AUTOSAR XML (schema 00046)
package /Appl_ComShell/ImplementationDataTypes
  19 x impl type, all with category=STRUCTURE:
    CrashStsSafe_1
      element Sts: implementation-data-type=uint8
      element Chks: implementation-data-type=uint8
      element Cntr: implementation-data-type=uint8
    EngSt1WdSts_1
      element EngSt1WdSts: implementation-data-type=uint8
      element Chks: implementation-data-type=uint8
      element Cntr: implementation-data-type=uint8
    EscVariantToDmc_1
      element EscVariantToDmc: implementation-data-type=uint8
      element Chks: implementation-data-type=uint8
      element Cntr: implementation-data-type=uint8
    HvSysRlySts_1
      element HvSysRlySts: implementation-data-type=uint8
      element Cntr: implementation-data-type=uint8
      element Chks: implementation-data-type=uint8
    PtTqAtAxleReq_1
      4 x element, all with category=TYPE_REFERENCE:
        PtTqAtAxleFrntReq: implementation-data-type=sint16
        PtTqAtAxleReReq: implementation-data-type=sint16
        Chks: implementation-data-type=uint8
        Cntr: implementation-data-type=uint8
    StcStsToDmc_1
      6 x element, all with category=TYPE_REFERENCE:
        StcStsToDmcFrnt: implementation-data-type=uint8
        StcStsToDmcRear: implementation-data-type=uint8
        EngRotTarSpdDMCFrnt: implementation-data-type=uint16
        EngRotTarSpdDMCRear: implementation-data-type=uint16
        Chks: implementation-data-type=uint8
        Cntr: implementation-data-type=uint8
    VehModMngtGlbSafe1_2
      10 x element, all with category=TYPE_REFERENCE, implementation-data-type=uint8:
        UsgModSts
        CarModSts1
        CarModSubtypWdCarModSubtyp
        EgyLvlElecMai
        EgyLvlElecSubtyp
        PwrLvlElecMai
        PwrLvlElecSubtyp
        FltEgyCnsWdSts
        Chks
        Cntr
    VehMtnStSafe1_2
      element VehMtnSt: implementation-data-type=uint8
      element VehMtnStChks: implementation-data-type=uint8
      element VehMtnStCntr: implementation-data-type=uint8
    VehSpdLgtSafe1_3
      4 x element, all with category=TYPE_REFERENCE:
        VehSpdLgtA: implementation-data-type=uint16
        VehSpdLgtQf: implementation-data-type=uint8
        VehSpdLgtCntr: implementation-data-type=uint8
        VehSpdLgtChks: implementation-data-type=uint8
    WhlMotSysTqAllwd_3
      element WhlMotSysTqAllwd: implementation-data-type=uint8
      element Chks: implementation-data-type=uint8
      element Cntr: implementation-data-type=uint8
    ImobEngMgrReq_2
      8 x element, all with category=TYPE_REFERENCE, implementation-data-type=uint8:
        ImobEngMgrCmdTar1
        ImobEngDataMgrReq{0..6}
    SysU_4
      element SysU: implementation-data-type=uint8
      element SysUQf: implementation-data-type=uint8
    DmcStsToEsc_1
      5 x element, all with category=TYPE_REFERENCE:
        DmcSts: implementation-data-type=uint8
        DmcActAppTarTq: implementation-data-type=sint16
        Cntr: implementation-data-type=uint8
        Chks: implementation-data-type=uint8
        DmcSWInfo: implementation-data-type=uint16
    SpdSgnSafe_1
      4 x element, all with category=TYPE_REFERENCE:
        IsgSpdWSgnTyp: implementation-data-type=sint16
        Chks: implementation-data-type=uint8
        Cntr: implementation-data-type=uint8
        Qf: implementation-data-type=uint8
    IsgTqActSafe2_4
      4 x element, all with category=TYPE_REFERENCE:
        Cntr: implementation-data-type=uint8
        Chks: implementation-data-type=uint8
        QualityFactor: implementation-data-type=uint8
        IsgTqAct: implementation-data-type=uint16
    DevDataTyp64_2
      8 x element, all with category=TYPE_REFERENCE, implementation-data-type=uint8:
        Byte{0..7}
    ElecDrvGen_4
      16 x element, all with category=TYPE_REFERENCE, implementation-data-type=uint8:
        EMQnty
        EMSeqNr
        DTCSts
        DTCLow
        DTCMid
        DTCHig
        TypeInfo
        MotTAlrmSt
        InvrtTAlrmSt
        FltAlrmSt
        SpdAlrmSt
        IacAlrmSt
        UDcAlrmSt
        RslAlrmSt
        ADAlrmSt
        ModStatusRms
    ImobEngChk_2
      8 x element, all with category=TYPE_REFERENCE, implementation-data-type=uint8:
        ImobEngChkSts
        ImobEngDataChk{0..6}
    WhlMotSysTqAvl_2
      element TqAvlMax: implementation-data-type=uint16
      element TqAvlMin: implementation-data-type=uint16
package /Appl_ComShell/DataTypeMappingSets
  data type mapping set Appl_ComShell_DTMap
    data-type-maps:
      application-data-type=AlrmSt_2, implementation-data-type=uint8
      application-data-type=Ampr1_1, implementation-data-type=uint16
      application-data-type=AvlSts2_2, implementation-data-type=uint8
      application-data-type=CarModSts1_2, implementation-data-type=uint8
      application-data-type=CarTiGlb_2, implementation-data-type=uint32
      application-data-type=CooltFlow2_2, implementation-data-type=uint16
      application-data-type=CooltFlowForDtElec1_2, implementation-data-type=uint16
      application-data-type=CooltTHiResl_2, implementation-data-type=uint16
      application-data-type=CrashSts2_2, implementation-data-type=uint8
      application-data-type=DMC_1, implementation-data-type=uint8
      application-data-type=EngSt1_2, implementation-data-type=uint8
      application-data-type=FltEgyCns1_2, implementation-data-type=uint8
      application-data-type=FltIndcn_1, implementation-data-type=uint8
      application-data-type=FltLvl_1, implementation-data-type=uint8
      application-data-type=FrntHeatModEnad_1, implementation-data-type=uint8
      application-data-type=GearLvrIndcn2_2, implementation-data-type=uint8
      application-data-type=GenQf1_2, implementation-data-type=uint8
      application-data-type=HvActvnSts_2, implementation-data-type=uint8
      application-data-type=HvCoolg1_2, implementation-data-type=uint8
      application-data-type=HvT1_3, implementation-data-type=uint8
      application-data-type=HvTq1_2, implementation-data-type=uint16
      application-data-type=HvU1_2, implementation-data-type=uint16
      application-data-type=ImobEngMgrReqCmd_2, implementation-data-type=uint8
      application-data-type=ImobSts_2, implementation-data-type=uint8
      application-data-type=IsgHeatPwr_1, implementation-data-type=uint8
      application-data-type=IsgSpdWSgnTyp_2, implementation-data-type=sint16
      application-data-type=Len31_2, implementation-data-type=uint32
      application-data-type=ModStatusRms_2, implementation-data-type=uint8
      application-data-type=ModeDMC_1, implementation-data-type=uint8
      application-data-type=N1_2, implementation-data-type=uint16
      application-data-type=Nr5_2, implementation-data-type=uint8
      application-data-type=OnBdChrgrHndlSts1_2, implementation-data-type=uint8
      application-data-type=OnBdChrgrHndlSts_2, implementation-data-type=uint8
      application-data-type=OnOff1_2, implementation-data-type=uint8
      application-data-type=PLockParkRequest_1, implementation-data-type=uint8
      application-data-type=ParkSts_1, implementation-data-type=uint8
      application-data-type=Perc7_2, implementation-data-type=uint16
      application-data-type=PrpsnPwrLimMax_2, implementation-data-type=uint16
      application-data-type=PrpsnPwrLimMin_2, implementation-data-type=uint16
      application-data-type=QualityFactor_2, implementation-data-type=uint8
      application-data-type=Spd1_2, implementation-data-type=uint16
      application-data-type=T3_2, implementation-data-type=uint8
      application-data-type=Tq2_2, implementation-data-type=sint16
      application-data-type=Tq34_1, implementation-data-type=uint16
      application-data-type=Tq35_1, implementation-data-type=sint16
      application-data-type=U1_2, implementation-data-type=uint8
      application-data-type=UInt16_2, implementation-data-type=uint16
      application-data-type=UInt2_2, implementation-data-type=uint8
      application-data-type=UInt4_2, implementation-data-type=uint8
      application-data-type=UInt8_2, implementation-data-type=uint8
      application-data-type=UsgModSts1_2, implementation-data-type=uint8
      application-data-type=VehMtnSt2_2, implementation-data-type=uint8
      application-data-type=WhlMotSysActvDampgModCodSts_2, implementation-data-type=uint8
      application-data-type=WhlMotSysHeatFdBck_1, implementation-data-type=uint8
      application-data-type=WhlMotSysModStsTyp1_2, implementation-data-type=uint8
      application-data-type=WhlMotSysModStsTyp2_2, implementation-data-type=uint8
      application-data-type=CrashStsSafe_1, implementation-data-type=CrashStsSafe_1
      application-data-type=EngSt1WdSts_1, implementation-data-type=EngSt1WdSts_1
      application-data-type=EscVariantToDmc_1, implementation-data-type=EscVariantToDmc_1
      application-data-type=HvSysRlySts_1, implementation-data-type=HvSysRlySts_1
      application-data-type=PtTqAtAxleReq_1, implementation-data-type=PtTqAtAxleReq_1
      application-data-type=StcStsToDmc_1, implementation-data-type=StcStsToDmc_1
      application-data-type=VehModMngtGlbSafe1_2, implementation-data-type=VehModMngtGlbSafe1_2
      application-data-type=VehMtnStSafe1_2, implementation-data-type=VehMtnStSafe1_2
      application-data-type=VehSpdLgtSafe1_3, implementation-data-type=VehSpdLgtSafe1_3
      application-data-type=WhlMotSysTqAllwd_3, implementation-data-type=WhlMotSysTqAllwd_3
      application-data-type=ImobEngMgrReq_2, implementation-data-type=ImobEngMgrReq_2
      application-data-type=SysU_4, implementation-data-type=SysU_4
      application-data-type=DmcStsToEsc_1, implementation-data-type=DmcStsToEsc_1
      application-data-type=SpdSgnSafe_1, implementation-data-type=SpdSgnSafe_1
      application-data-type=IsgTqActSafe2_4, implementation-data-type=IsgTqActSafe2_4
      application-data-type=DevDataTyp64_2, implementation-data-type=DevDataTyp64_2
      application-data-type=ElecDrvGen_4, implementation-data-type=ElecDrvGen_4
      application-data-type=ImobEngChk_2, implementation-data-type=ImobEngChk_2
      application-data-type=WhlMotSysTqAvl_2, implementation-data-type=WhlMotSysTqAvl_2
package /Appl_ComShell/ComponentTypes
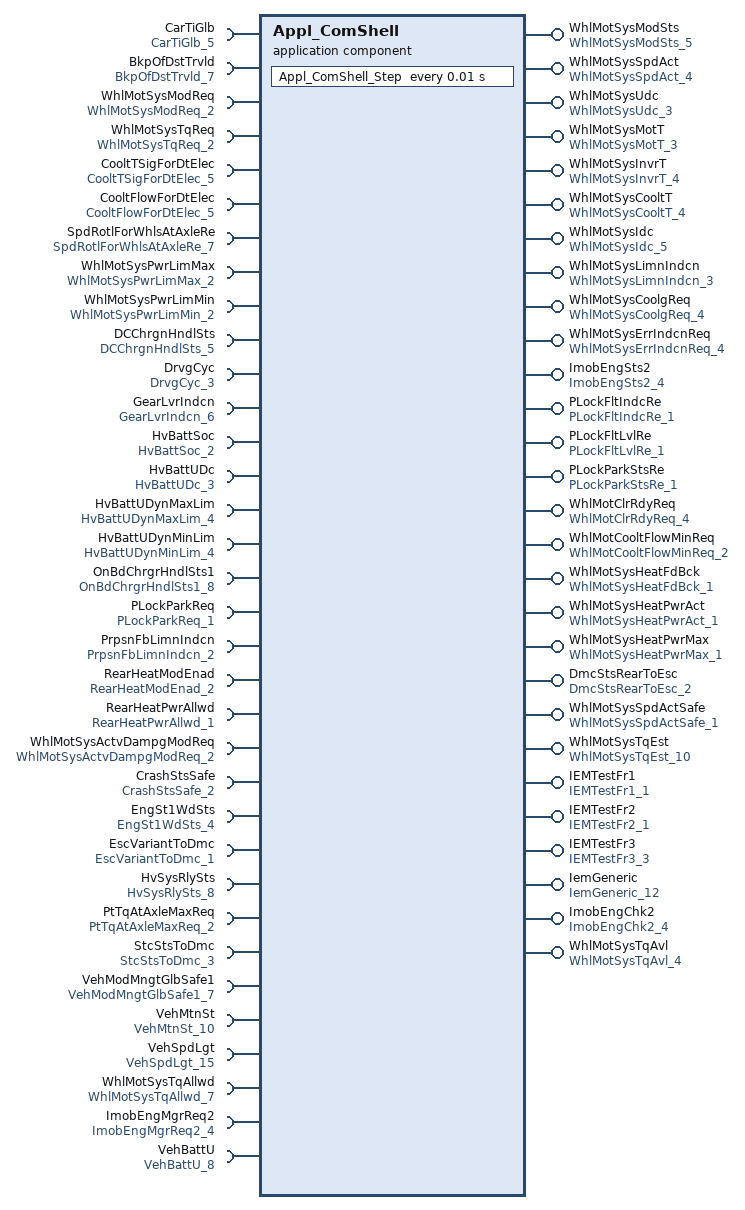
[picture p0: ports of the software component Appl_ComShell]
  application sw component type Appl_ComShell
    9 x require port:
      CarTiGlb: nonqueued-receiver-com-spec{data-element=CarTiGlb, init-value=0}, required-interface=CarTiGlb_5
      BkpOfDstTrvld: nonqueued-receiver-com-spec{data-element=BkpOfDstTrvld, init-value=0}, required-interface=BkpOfDstTrvld_7
      WhlMotSysModReq: nonqueued-receiver-com-spec{data-element=WhlMotSysModReq, init-value=0}, required-interface=WhlMotSysModReq_2
      WhlMotSysTqReq: nonqueued-receiver-com-spec{data-element=WhlMotSysTqReq, init-value=0}, required-interface=WhlMotSysTqReq_2
      CooltTSigForDtElec: nonqueued-receiver-com-spec{data-element=CooltTSigForDtElec, init-value=0}, required-interface=CooltTSigForDtElec_5
      CooltFlowForDtElec: nonqueued-receiver-com-spec{data-element=CooltFlowForDtElec, init-value=0}, required-interface=CooltFlowForDtElec_5
      SpdRotlForWhlsAtAxleRe: nonqueued-receiver-com-spec{data-element=SpdRotlForWhlsAtAxleRe, init-value=0}, required-interface=SpdRotlForWhlsAtAxleRe_7
      WhlMotSysPwrLimMax: nonqueued-receiver-com-spec{data-element=WhlMotSysPwrLimMax, init-value=0}, required-interface=WhlMotSysPwrLimMax_2
      WhlMotSysPwrLimMin: nonqueued-receiver-com-spec{data-element=WhlMotSysPwrLimMin, init-value=0}, required-interface=WhlMotSysPwrLimMin_2
    10 x provide port:
      WhlMotSysModSts: nonqueued-sender-com-spec{data-element=WhlMotSysModSts, init-value=0}, provided-interface=WhlMotSysModSts_5
      WhlMotSysSpdAct: nonqueued-sender-com-spec{data-element=WhlMotSysSpdAct, init-value=0}, provided-interface=WhlMotSysSpdAct_4
      WhlMotSysUdc: nonqueued-sender-com-spec{data-element=WhlMotSysUdc, init-value=0}, provided-interface=WhlMotSysUdc_3
      WhlMotSysMotT: nonqueued-sender-com-spec{data-element=WhlMotSysMotT, init-value=0}, provided-interface=WhlMotSysMotT_3
      WhlMotSysInvrT: nonqueued-sender-com-spec{data-element=WhlMotSysInvrT, init-value=0}, provided-interface=WhlMotSysInvrT_4
      WhlMotSysCooltT: nonqueued-sender-com-spec{data-element=WhlMotSysCooltT, init-value=0}, provided-interface=WhlMotSysCooltT_4
      WhlMotSysIdc: nonqueued-sender-com-spec{data-element=WhlMotSysIdc, init-value=0}, provided-interface=WhlMotSysIdc_5
      WhlMotSysLimnIndcn: nonqueued-sender-com-spec{data-element=WhlMotSysLimnIndcn, init-value=0}, provided-interface=WhlMotSysLimnIndcn_3
      WhlMotSysCoolgReq: nonqueued-sender-com-spec{data-element=WhlMotSysCoolgReq, init-value=0}, provided-interface=WhlMotSysCoolgReq_4
      WhlMotSysErrIndcnReq: nonqueued-sender-com-spec{data-element=WhlMotSysErrIndcnReq, init-value=0}, provided-interface=WhlMotSysErrIndcnReq_4
    7 x require port:
      DCChrgnHndlSts: nonqueued-receiver-com-spec{data-element=DCChrgnHndlSts, init-value=0}, required-interface=DCChrgnHndlSts_5
      DrvgCyc: nonqueued-receiver-com-spec{data-element=DrvgCyc, init-value=0}, required-interface=DrvgCyc_3
      GearLvrIndcn: nonqueued-receiver-com-spec{data-element=GearLvrIndcn, init-value=0}, required-interface=GearLvrIndcn_6
      HvBattSoc: nonqueued-receiver-com-spec{data-element=HvBattSoc, init-value=0}, required-interface=HvBattSoc_2
      HvBattUDc: nonqueued-receiver-com-spec{data-element=HvBattUDc, init-value=0}, required-interface=HvBattUDc_3
      HvBattUDynMaxLim: nonqueued-receiver-com-spec{data-element=HvBattUDynMaxLim, init-value=0}, required-interface=HvBattUDynMaxLim_4
      HvBattUDynMinLim: nonqueued-receiver-com-spec{data-element=HvBattUDynMinLim, init-value=0}, required-interface=HvBattUDynMinLim_4
    provide port ImobEngSts2: nonqueued-sender-com-spec{data-element=ImobEngSts2, init-value=0}, provided-interface=ImobEngSts2_4
    require port OnBdChrgrHndlSts1: nonqueued-receiver-com-spec{data-element=OnBdChrgrHndlSts1, init-value=0}, required-interface=OnBdChrgrHndlSts1_8
    provide port PLockFltIndcRe: nonqueued-sender-com-spec{data-element=PLockFltIndcRe, init-value=0}, provided-interface=PLockFltIndcRe_1
    provide port PLockFltLvlRe: nonqueued-sender-com-spec{data-element=PLockFltLvlRe, init-value=0}, provided-interface=PLockFltLvlRe_1
    require port PLockParkReq: nonqueued-receiver-com-spec{data-element=PLockParkReq, init-value=0}, required-interface=PLockParkReq_1
    provide port PLockParkStsRe: nonqueued-sender-com-spec{data-element=PLockParkStsRe, init-value=0}, provided-interface=PLockParkStsRe_1
    require port PrpsnFbLimnIndcn: nonqueued-receiver-com-spec{data-element=PrpsnFbLimnIndcn, init-value=0}, required-interface=PrpsnFbLimnIndcn_2
    require port RearHeatModEnad: nonqueued-receiver-com-spec{data-element=RearHeatModEnad, init-value=0}, required-interface=RearHeatModEnad_2
    require port RearHeatPwrAllwd: nonqueued-receiver-com-spec{data-element=RearHeatPwrAllwd, init-value=0}, required-interface=RearHeatPwrAllwd_1
    provide port WhlMotClrRdyReq: nonqueued-sender-com-spec{data-element=WhlMotClrRdyReq, init-value=0}, provided-interface=WhlMotClrRdyReq_4
    provide port WhlMotCooltFlowMinReq: nonqueued-sender-com-spec{data-element=WhlMotCooltFlowMinReq, init-value=0}, provided-interface=WhlMotCooltFlowMinReq_2
    require port WhlMotSysActvDampgModReq: nonqueued-receiver-com-spec{data-element=WhlMotSysActvDampgModReq, init-value=0}, required-interface=WhlMotSysActvDampgModReq_2
    provide port WhlMotSysHeatFdBck: nonqueued-sender-com-spec{data-element=WhlMotSysHeatFdBck, init-value=0}, provided-interface=WhlMotSysHeatFdBck_1
    provide port WhlMotSysHeatPwrAct: nonqueued-sender-com-spec{data-element=WhlMotSysHeatPwrAct, init-value=0}, provided-interface=WhlMotSysHeatPwrAct_1
    provide port WhlMotSysHeatPwrMax: nonqueued-sender-com-spec{data-element=WhlMotSysHeatPwrMax, init-value=0}, provided-interface=WhlMotSysHeatPwrMax_1
    12 x require port:
      CrashStsSafe: nonqueued-receiver-com-spec{data-element=CrashStsSafe, init-value=fields=[Sts:0, Chks:0, Cntr:0]}, required-interface=CrashStsSafe_2
      EngSt1WdSts: nonqueued-receiver-com-spec{data-element=EngSt1WdSts, init-value=fields=[EngSt1WdSts:0, Chks:0, Cntr:0]}, required-interface=EngSt1WdSts_4
      EscVariantToDmc: nonqueued-receiver-com-spec{data-element=EscVariantToDmc, init-value=fields=[EscVariantToDmc:0, Chks:0, Cntr:0]}, required-interface=EscVariantToDmc_1
      HvSysRlySts: nonqueued-receiver-com-spec{data-element=HvSysRlySts, init-value=fields=[HvSysRlySts:0, Cntr:0, Chks:0]}, required-interface=HvSysRlySts_8
      PtTqAtAxleMaxReq: nonqueued-receiver-com-spec{data-element=PtTqAtAxleMaxReq, init-value=fields=[PtTqAtAxleFrntReq:0, PtTqAtAxleReReq:0, Chks:0, Cntr:0]}, required-interface=PtTqAtAxleMaxReq_2
      StcStsToDmc: nonqueued-receiver-com-spec{data-element=StcStsToDmc, init-value=fields=[StcStsToDmcFrnt:0, StcStsToDmcRear:0, EngRotTarSpdDMCFrnt:0, EngRotTarSpdDMCRear:0, Chks:0, Cntr:0]}, required-interface=StcStsToDmc_3
      VehModMngtGlbSafe1: nonqueued-receiver-com-spec{data-element=VehModMngtGlbSafe1, init-value=fields=[UsgModSts:0, CarModSts1:0, CarModSubtypWdCarModSubtyp:0, EgyLvlElecMai:0, EgyLvlElecSubtyp:0, PwrLvlElecMai:0, PwrLvlElecSubtyp:0, FltEgyCnsWdSts:0, Chks:0, Cntr:0]}, required-interface=VehModMngtGlbSafe1_7
      VehMtnSt: nonqueued-receiver-com-spec{data-element=VehMtnSt, init-value=fields=[VehMtnSt:0, VehMtnStChks:0, VehMtnStCntr:0]}, required-interface=VehMtnSt_10
      VehSpdLgt: nonqueued-receiver-com-spec{data-element=VehSpdLgt, init-value=fields=[VehSpdLgtA:0, VehSpdLgtQf:0, VehSpdLgtCntr:0, VehSpdLgtChks:0]}, required-interface=VehSpdLgt_15
      WhlMotSysTqAllwd: nonqueued-receiver-com-spec{data-element=WhlMotSysTqAllwd, init-value=fields=[WhlMotSysTqAllwd:0, Chks:0, Cntr:0]}, required-interface=WhlMotSysTqAllwd_7
      ImobEngMgrReq2: nonqueued-receiver-com-spec{data-element=ImobEngMgrReq2, init-value=fields=[ImobEngMgrCmdTar1:0, ImobEngDataMgrReq0:0, ImobEngDataMgrReq1:0, ImobEngDataMgrReq2:0, ImobEngDataMgrReq3:0, ImobEngDataMgrReq4:0, ImobEngDataMgrReq5:0, ImobEngDataMgrReq6:0]}, required-interface=ImobEngMgrReq2_4
      VehBattU: nonqueued-receiver-com-spec{data-element=VehBattU, init-value=fields=[SysU:0, SysUQf:0]}, required-interface=VehBattU_8
    9 x provide port:
      DmcStsRearToEsc: nonqueued-sender-com-spec{data-element=DmcStsRearToEsc, init-value=fields=[DmcSts:0, DmcActAppTarTq:0, Cntr:0, Chks:0, DmcSWInfo:0]}, provided-interface=DmcStsRearToEsc_2
      WhlMotSysSpdActSafe: nonqueued-sender-com-spec{data-element=WhlMotSysSpdActSafe, init-value=fields=[IsgSpdWSgnTyp:0, Chks:0, Cntr:0, Qf:0]}, provided-interface=WhlMotSysSpdActSafe_1
      WhlMotSysTqEst: nonqueued-sender-com-spec{data-element=WhlMotSysTqEst, init-value=fields=[Cntr:0, Chks:0, QualityFactor:0, IsgTqAct:0]}, provided-interface=WhlMotSysTqEst_10
      IEMTestFr1: nonqueued-sender-com-spec{data-element=IEMTestFr1, init-value=fields=[Byte0:0, Byte1:0, Byte2:0, Byte3:0, Byte4:0, Byte5:0, Byte6:0, Byte7:0]}, provided-interface=IEMTestFr1_1
      IEMTestFr2: nonqueued-sender-com-spec{data-element=IEMTestFr2, init-value=fields=[Byte0:0, Byte1:0, Byte2:0, Byte3:0, Byte4:0, Byte5:0, Byte6:0, Byte7:0]}, provided-interface=IEMTestFr2_1
      IEMTestFr3: nonqueued-sender-com-spec{data-element=IEMTestFr3, init-value=fields=[Byte0:0, Byte1:0, Byte2:0, Byte3:0, Byte4:0, Byte5:0, Byte6:0, Byte7:0]}, provided-interface=IEMTestFr3_3
      IemGeneric: nonqueued-sender-com-spec{data-element=IemGeneric, init-value=fields=[EMQnty:0, EMSeqNr:0, DTCSts:0, DTCLow:0, DTCMid:0, DTCHig:0, TypeInfo:0, MotTAlrmSt:0, InvrtTAlrmSt:0, FltAlrmSt:0, SpdAlrmSt:0, IacAlrmSt:0, UDcAlrmSt:0, RslAlrmSt:0, ADAlrmSt:0, ModStatusRms:0]}, provided-interface=IemGeneric_12
      ImobEngChk2: nonqueued-sender-com-spec{data-element=ImobEngChk2, init-value=fields=[ImobEngChkSts:0, ImobEngDataChk0:0, ImobEngDataChk1:0, ImobEngDataChk2:0, ImobEngDataChk3:0, ImobEngDataChk4:0, ImobEngDataChk5:0, ImobEngDataChk6:0]}, provided-interface=ImobEngChk2_4
      WhlMotSysTqAvl: nonqueued-sender-com-spec{data-element=WhlMotSysTqAvl, init-value=fields=[TqAvlMax:0, TqAvlMin:0]}, provided-interface=WhlMotSysTqAvl_4
    behavior Appl_ComShellInternalBehavior: data-type-mapping=Appl_ComShell_DTMap, handle-termination-and-restart=NO-SUPPORT
      timing event RE_Appl_ComShell_Step: start-on-event=Appl_ComShell_Step, period=0.01
      runnable Appl_ComShell_Step
        data-receive-point-by-arguments:
          34 x access:
            DRA_CarTiGlb: accessed-variable=CarTiGlb.CarTiGlb
            DRA_BkpOfDstTrvld: accessed-variable=BkpOfDstTrvld.BkpOfDstTrvld
            DRA_WhlMotSysModReq: accessed-variable=WhlMotSysModReq.WhlMotSysModReq
            DRA_WhlMotSysTqReq: accessed-variable=WhlMotSysTqReq.WhlMotSysTqReq
            DRA_CooltTSigForDtElec: accessed-variable=CooltTSigForDtElec.CooltTSigForDtElec
            DRA_CooltFlowForDtElec: accessed-variable=CooltFlowForDtElec.CooltFlowForDtElec
            DRA_SpdRotlForWhlsAtAxleRe: accessed-variable=SpdRotlForWhlsAtAxleRe.SpdRotlForWhlsAtAxleRe
            DRA_WhlMotSysPwrLimMax: accessed-variable=WhlMotSysPwrLimMax.WhlMotSysPwrLimMax
            DRA_WhlMotSysPwrLimMin: accessed-variable=WhlMotSysPwrLimMin.WhlMotSysPwrLimMin
            DRA_DCChrgnHndlSts: accessed-variable=DCChrgnHndlSts.DCChrgnHndlSts
            DRA_DrvgCyc: accessed-variable=DrvgCyc.DrvgCyc
            DRA_GearLvrIndcn: accessed-variable=GearLvrIndcn.GearLvrIndcn
            DRA_HvBattSoc: accessed-variable=HvBattSoc.HvBattSoc
            DRA_HvBattUDc: accessed-variable=HvBattUDc.HvBattUDc
            DRA_HvBattUDynMaxLim: accessed-variable=HvBattUDynMaxLim.HvBattUDynMaxLim
            DRA_HvBattUDynMinLim: accessed-variable=HvBattUDynMinLim.HvBattUDynMinLim
            DRA_OnBdChrgrHndlSts1: accessed-variable=OnBdChrgrHndlSts1.OnBdChrgrHndlSts1
            DRA_PLockParkReq: accessed-variable=PLockParkReq.PLockParkReq
            DRA_PrpsnFbLimnIndcn: accessed-variable=PrpsnFbLimnIndcn.PrpsnFbLimnIndcn
            DRA_RearHeatModEnad: accessed-variable=RearHeatModEnad.RearHeatModEnad
            DRA_RearHeatPwrAllwd: accessed-variable=RearHeatPwrAllwd.RearHeatPwrAllwd
            DRA_WhlMotSysActvDampgModReq: accessed-variable=WhlMotSysActvDampgModReq.WhlMotSysActvDampgModReq
            DRA_CrashStsSafe: accessed-variable=CrashStsSafe.CrashStsSafe
            DRA_EngSt1WdSts: accessed-variable=EngSt1WdSts.EngSt1WdSts
            DRA_EscVariantToDmc: accessed-variable=EscVariantToDmc.EscVariantToDmc
            DRA_HvSysRlySts: accessed-variable=HvSysRlySts.HvSysRlySts
            DRA_PtTqAtAxleMaxReq: accessed-variable=PtTqAtAxleMaxReq.PtTqAtAxleMaxReq
            DRA_StcStsToDmc: accessed-variable=StcStsToDmc.StcStsToDmc
            DRA_VehModMngtGlbSafe1: accessed-variable=VehModMngtGlbSafe1.VehModMngtGlbSafe1
            DRA_VehMtnSt: accessed-variable=VehMtnSt.VehMtnSt
            DRA_VehSpdLgt: accessed-variable=VehSpdLgt.VehSpdLgt
            DRA_WhlMotSysTqAllwd: accessed-variable=WhlMotSysTqAllwd.WhlMotSysTqAllwd
            DRA_ImobEngMgrReq2: accessed-variable=ImobEngMgrReq2.ImobEngMgrReq2
            DRA_VehBattU: accessed-variable=VehBattU.VehBattU
        data-send-points:
          28 x access:
            DSP_WhlMotSysModSts: accessed-variable=WhlMotSysModSts.WhlMotSysModSts
            DSP_WhlMotSysSpdAct: accessed-variable=WhlMotSysSpdAct.WhlMotSysSpdAct
            DSP_WhlMotSysUdc: accessed-variable=WhlMotSysUdc.WhlMotSysUdc
            DSP_WhlMotSysMotT: accessed-variable=WhlMotSysMotT.WhlMotSysMotT
            DSP_WhlMotSysInvrT: accessed-variable=WhlMotSysInvrT.WhlMotSysInvrT
            DSP_WhlMotSysCooltT: accessed-variable=WhlMotSysCooltT.WhlMotSysCooltT
            DSP_WhlMotSysIdc: accessed-variable=WhlMotSysIdc.WhlMotSysIdc
            DSP_WhlMotSysLimnIndcn: accessed-variable=WhlMotSysLimnIndcn.WhlMotSysLimnIndcn
            DSP_WhlMotSysCoolgReq: accessed-variable=WhlMotSysCoolgReq.WhlMotSysCoolgReq
            DSP_WhlMotSysErrIndcnReq: accessed-variable=WhlMotSysErrIndcnReq.WhlMotSysErrIndcnReq
            DSP_ImobEngSts2: accessed-variable=ImobEngSts2.ImobEngSts2
            DSP_PLockFltIndcRe: accessed-variable=PLockFltIndcRe.PLockFltIndcRe
            DSP_PLockFltLvlRe: accessed-variable=PLockFltLvlRe.PLockFltLvlRe
            DSP_PLockParkStsRe: accessed-variable=PLockParkStsRe.PLockParkStsRe
            DSP_WhlMotClrRdyReq: accessed-variable=WhlMotClrRdyReq.WhlMotClrRdyReq
            DSP_WhlMotCooltFlowMinReq: accessed-variable=WhlMotCooltFlowMinReq.WhlMotCooltFlowMinReq
            DSP_WhlMotSysHeatFdBck: accessed-variable=WhlMotSysHeatFdBck.WhlMotSysHeatFdBck
            DSP_WhlMotSysHeatPwrAct: accessed-variable=WhlMotSysHeatPwrAct.WhlMotSysHeatPwrAct
            DSP_WhlMotSysHeatPwrMax: accessed-variable=WhlMotSysHeatPwrMax.WhlMotSysHeatPwrMax
            DSP_DmcStsRearToEsc: accessed-variable=DmcStsRearToEsc.DmcStsRearToEsc
            DSP_WhlMotSysSpdActSafe: accessed-variable=WhlMotSysSpdActSafe.WhlMotSysSpdActSafe
            DSP_WhlMotSysTqEst: accessed-variable=WhlMotSysTqEst.WhlMotSysTqEst
            DSP_IEMTestFr{1..3}: accessed-variable=IEMTestFr{1..3}.IEMTestFr{1..3}
            DSP_IemGeneric: accessed-variable=IemGeneric.IemGeneric
            DSP_ImobEngChk2: accessed-variable=ImobEngChk2.ImobEngChk2
            DSP_WhlMotSysTqAvl: accessed-variable=WhlMotSysTqAvl.WhlMotSysTqAvl
  swc implementation Appl_ComShellImplementation: programming-language=C, sw-version=0.6.0, behavior=Appl_ComShellInternalBehavior
